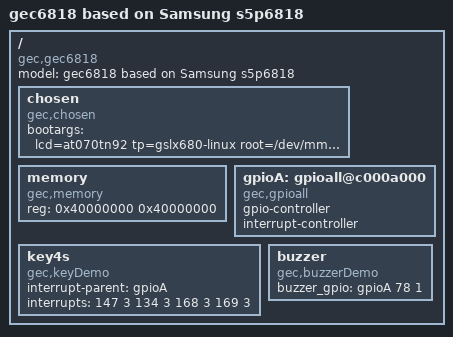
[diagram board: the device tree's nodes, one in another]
/dts-v1/;
/include/ "skeleton.dtsi"

/ {
    model = "gec6818 based on Samsung s5p6818";
    compatible = "gec,gec6818";

    chosen {
        compatible = "gec,chosen";
        bootargs = "lcd=at070tn92 tp=gslx680-linux root=/dev/mmcblk0p2 rootfstype=ext4 rw";
    };

    memory {
        compatible = "gec,memory";
        device_type = "memory";
        reg = <0x40000000 0x40000000>; // DDR的内存起始地址和 ~ 内存的大小
    };

    // 控制器结点
    gpioA:gpioall@c000a000 {
        compatible = "gec,gpioall";  // 兼容性标识，用于匹配驱动程序

        gpio-controller;            // 可以作为GPIO控制器
        #gpio-cells = <2>;          // 作为GPIO口控制器，你得需要两个单元表示【哪个GPIO口，具体那种电平信号】

        interrupt-controller;       // 可以作为中断控制器
        #interrupt-cells = <2>;     // 作为中断控制器，你得需要两个单元表示【哪个中断口(中断号)，具体那种中断触发方式】
    };

    // 按键设备节点
    key4s{
        compatible = "gec,keyDemo";     // 兼容性标识，用于匹配驱动程序
        interrupt-parent = <&gpioA>;    // 当前设备节点的中断父控制器是gpioA。
        interrupts = <147 3 
                      134 3
                      168 3
                      169 3>;           // 中断号和中断触发方式
    };

    // 蜂鸣器设备节点
    buzzer{
        compatible = "gec,buzzerDemo";     // 兼容性标识，用于匹配驱动程序
        buzzer_gpio = <&gpioA 78 1>;       // GPIOC14的端口号为：【2 * 32 + 14】
    };

};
